VERSION ""

NS_ :

BS_:

BU_: CTRL UUT

BO_ 2565855488 CTRL1: 8 CTRL
 SG_ Command M : 0|6@1+ (1,0) [0|63] ""  UUT
 SG_ Reserved_Prefix : 6|2@1+ (1,0) [0|3] ""  UUT
 SG_ Spare_D5 m1 : 8|2@1+ (1,0) [0|3] ""  UUT
 SG_ Enable_DIGIN m1 : 10|2@1+ (1,0) [0|3] ""  UUT
 SG_ Enable_AD2 m1 : 12|2@1+ (1,0) [0|3] ""  UUT
 SG_ Enable_AD3 m1 : 14|2@1+ (1,0) [0|3] ""  UUT
 SG_ Enable_AD4 m1 : 16|2@1+ (1,0) [0|3] ""  UUT
 SG_ SaveSettings m1 : 18|2@1+ (1,0) [0|3] ""  UUT
 SG_ ADRaw m1 : 20|2@1+ (1,0) [0|3] ""  UUT
 SG_ Reset_Sensor_Power_Faults m1 : 22|2@1+ (1,0) [0|3] ""  UUT
 SG_ Enable_DPLF2 m1 : 24|2@1+ (1,0) [0|3] ""  UUT
 SG_ Enable_FAULT m1 : 26|2@1+ (1,0) [0|3] ""  UUT
 SG_ Ratiometric_AD2_AD3 m1 : 28|2@1+ (1,0) [0|3] ""  UUT
 SG_ Spare_D16 m1 : 30|2@1+ (1,0) [0|3] ""  UUT
 SG_ Protocol_Mode m1 : 32|8@1+ (1,0) [0|255] ""  UUT
 SG_ ID1 m1 : 56|8@1+ (1,0) [0|255] ""  UUT
 SG_ Request_Key m16 : 8|8@1+ (1,0) [0|255] ""  UUT
 SG_ Req_Config_Data_D9 m16 : 16|2@1+ (1,0) [0|3] ""  UUT
 SG_ Req_Calibration_Data_D10 m16 : 18|2@1+ (1,0) [0|3] ""  UUT
 SG_ Reset_Factory_Settings_D11 m16 : 20|2@1+ (1,0) [0|3] ""  UUT
 SG_ Reset_Fault_Counters_D12 m16 : 22|2@1+ (1,0) [0|3] ""  UUT
 SG_ Erase_EEPROM_D13 m16 : 24|2@1+ (1,0) [0|3] ""  UUT
 SG_ Unlock_Key_1 m17 : 8|8@1+ (1,0) [0|255] ""  UUT
 SG_ Unlock_Key_2 m17 : 16|8@1+ (1,0) [0|255] ""  UUT
 SG_ Source_Address_Set m17 : 24|8@1+ (1,0) [0|255] ""  UUT
 SG_ Bit_Rate_Set m17 : 32|8@1+ (1,0) [0|255] ""  UUT
 SG_ CAN_Term_D31 m17 : 60|2@1+ (1,0) [0|3] ""  UUT
 SG_ Reboot_Module_D32 m17 : 62|2@1+ (1,0) [0|3] ""  UUT
 SG_ Information_Index m32 : 8|8@1+ (1,0) [0|255] ""  UUT

BO_ 2565800153 STAT: 8 UUT
 SG_ Response M : 0|6@1+ (1,0) [0|63] ""  CTRL
 SG_ Reserved_Prefix : 6|2@1+ (1,0) [0|3] ""  CTRL
 SG_ Active_Protocol_Mode m0 : 24|8@1+ (1,0) [0|255] ""  CTRL
 SG_ Active_Fault_Code m0 : 32|8@1+ (1,0) [0|255] ""  CTRL
 SG_ UserID m0 : 40|8@1+ (1,0) [0|255] ""  CTRL
 SG_ Software_Version m0 : 48|8@1+ (1,0) [0|255] ""  CTRL
 SG_ Software_Revision m0 : 56|8@1+ (1,0) [0|255] ""  CTRL
 SG_ Spare_D5 m1 : 8|2@1+ (1,0) [0|3] ""  CTRL
 SG_ Enable_DIGIN m1 : 10|2@1+ (1,0) [0|3] ""  CTRL
 SG_ Enable_AD2 m1 : 12|2@1+ (1,0) [0|3] ""  CTRL
 SG_ Enable_AD3 m1 : 14|2@1+ (1,0) [0|3] ""  CTRL
 SG_ Enable_AD4 m1 : 16|2@1+ (1,0) [0|3] ""  CTRL
 SG_ SaveSettings m1 : 18|2@1+ (1,0) [0|3] ""  CTRL
 SG_ ADRaw m1 : 20|2@1+ (1,0) [0|3] ""  CTRL
 SG_ Reset_Sensor_Power_Faults m1 : 22|2@1+ (1,0) [0|3] ""  CTRL
 SG_ Enable_DPLF2 m1 : 24|2@1+ (1,0) [0|3] ""  CTRL
 SG_ Enable_FAULT m1 : 26|2@1+ (1,0) [0|3] ""  CTRL
 SG_ Ratiometric_AD2_AD3 m1 : 28|2@1+ (1,0) [0|3] ""  CTRL
 SG_ Spare_D16 m1 : 30|2@1+ (1,0) [0|3] ""  CTRL
 SG_ Protocol_Mode m1 : 32|8@1+ (1,0) [0|255] ""  CTRL
 SG_ ID1 m1 : 56|8@1+ (1,0) [0|255] ""  CTRL
 SG_ Request_Key m16 : 8|8@1+ (1,0) [0|255] ""  CTRL
 SG_ Req_Config_Data_D9 m16 : 16|2@1+ (1,0) [0|3] ""  CTRL
 SG_ Req_Calibration_Data_D10 m16 : 18|2@1+ (1,0) [0|3] ""  CTRL
 SG_ Reset_Factory_Settings_D11 m16 : 20|2@1+ (1,0) [0|3] ""  CTRL
 SG_ Reset_Fault_Counters_D12 m16 : 22|2@1+ (1,0) [0|3] ""  CTRL
 SG_ Erase_EEPROM_D13 m16 : 24|2@1+ (1,0) [0|3] ""  CTRL
 SG_ Unlock_Key_1 m17 : 8|8@1+ (1,0) [0|255] ""  CTRL
 SG_ Unlock_Key_2 m17 : 16|8@1+ (1,0) [0|255] ""  CTRL
 SG_ Source_Address_Set m17 : 24|8@1+ (1,0) [0|255] ""  CTRL
 SG_ Bit_Rate_Set m17 : 32|8@1+ (1,0) [0|255] ""  CTRL
 SG_ CAN_Term_D31 m17 : 60|2@1+ (1,0) [0|3] ""  CTRL
 SG_ Reboot_Module_D32 m17 : 62|2@1+ (1,0) [0|3] ""  CTRL
 SG_ Info_Data_Byte2 m32 : 8|8@1+ (1,0) [0|255] ""  CTRL
 SG_ Info_Data_Byte3 m32 : 16|8@1+ (1,0) [0|255] ""  CTRL
 SG_ Info_Data_Byte4 m32 : 24|8@1+ (1,0) [0|255] ""  CTRL
 SG_ Info_Data_Byte5 m32 : 32|8@1+ (1,0) [0|255] ""  CTRL
 SG_ Info_Data_Byte6 m32 : 40|8@1+ (1,0) [0|255] ""  CTRL
 SG_ Info_Data_Byte7 m32 : 48|8@1+ (1,0) [0|255] ""  CTRL

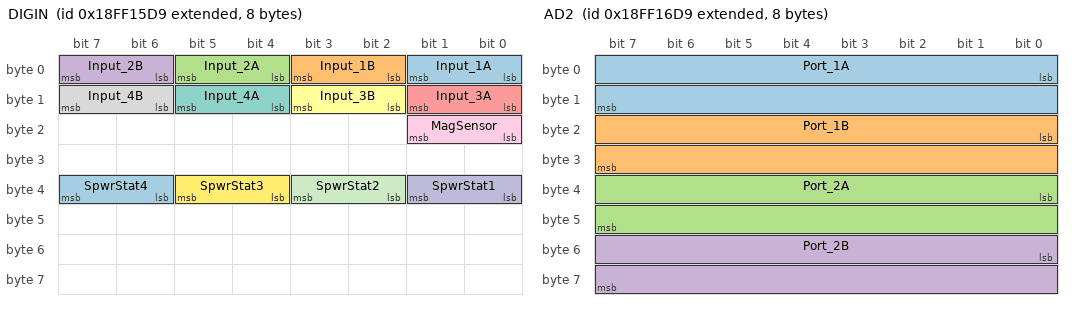
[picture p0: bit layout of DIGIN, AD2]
BO_ 2566854105 DIGIN: 8 UUT
 SG_ Input_1A : 0|2@1+ (1,0) [0|3] ""  CTRL
 SG_ Input_1B : 2|2@1+ (1,0) [0|3] ""  CTRL
 SG_ Input_2A : 4|2@1+ (1,0) [0|3] ""  CTRL
 SG_ Input_2B : 6|2@1+ (1,0) [0|3] ""  CTRL
 SG_ Input_3A : 8|2@1+ (1,0) [0|3] ""  CTRL
 SG_ Input_3B : 10|2@1+ (1,0) [0|3] ""  CTRL
 SG_ Input_4A : 12|2@1+ (1,0) [0|3] ""  CTRL
 SG_ Input_4B : 14|2@1+ (1,0) [0|3] ""  CTRL
 SG_ MagSensor : 16|2@1+ (1,0) [0|3] ""  CTRL
 SG_ SpwrStat1 : 32|2@1+ (1,0) [0|3] ""  CTRL
 SG_ SpwrStat2 : 34|2@1+ (1,0) [0|3] ""  CTRL
 SG_ SpwrStat3 : 36|2@1+ (1,0) [0|3] ""  CTRL
 SG_ SpwrStat4 : 38|2@1+ (1,0) [0|3] ""  CTRL

BO_ 2566854361 AD2: 8 UUT
 SG_ Port_1A : 0|16@1+ (0.001,0) [0|5] "V"  CTRL
 SG_ Port_1B : 16|16@1+ (0.001,0) [0|5] "V"  CTRL
 SG_ Port_2A : 32|16@1+ (0.001,0) [0|5] "V"  CTRL
 SG_ Port_2B : 48|16@1+ (0.001,0) [0|5] "V"  CTRL

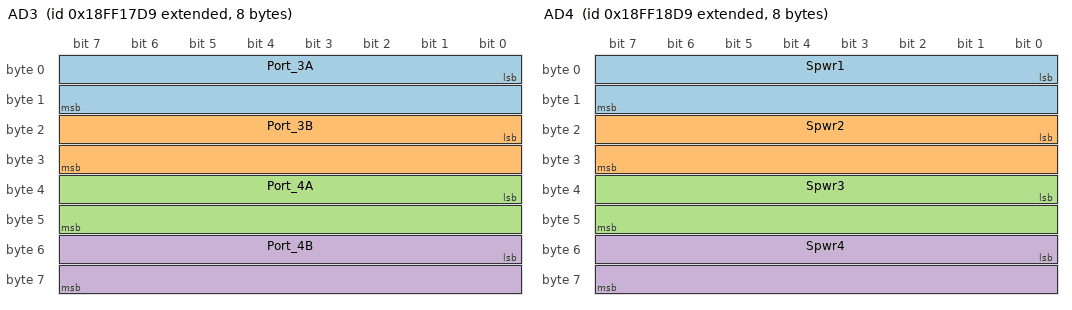
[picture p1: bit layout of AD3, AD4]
BO_ 2566854617 AD3: 8 UUT
 SG_ Port_3A : 0|16@1+ (0.001,0) [0|5] "V"  CTRL
 SG_ Port_3B : 16|16@1+ (0.001,0) [0|5] "V"  CTRL
 SG_ Port_4A : 32|16@1+ (0.001,0) [0|5] "V"  CTRL
 SG_ Port_4B : 48|16@1+ (0.001,0) [0|5] "V"  CTRL

BO_ 2566854873 AD4: 8 UUT
 SG_ Spwr1 : 0|16@1+ (0.001,0) [0|5] "V"  CTRL
 SG_ Spwr2 : 16|16@1+ (0.001,0) [0|5] "V"  CTRL
 SG_ Spwr3 : 32|16@1+ (0.001,0) [0|5] "V"  CTRL
 SG_ Spwr4 : 48|16@1+ (0.001,0) [0|5] "V"  CTRL

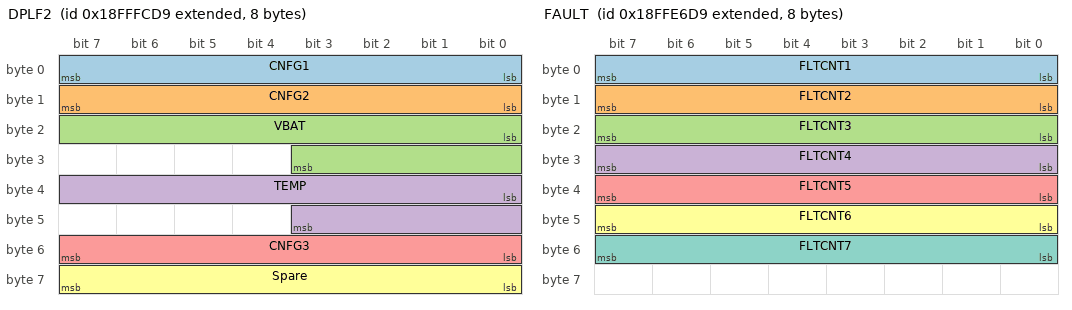
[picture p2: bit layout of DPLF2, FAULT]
BO_ 2566913241 DPLF2: 8 UUT
 SG_ CNFG1 : 0|8@1+ (1,0) [1|50] ""  CTRL
 SG_ CNFG2 : 8|8@1+ (1,0) [1|36] ""  CTRL
 SG_ VBAT : 16|12@1+ (0.1,0) [0|32] "V"  CTRL
 SG_ TEMP : 32|12@1+ (0.1,-100) [-100|300] "degF"  CTRL
 SG_ CNFG3 : 48|8@1+ (1,0) [0|240] ""  CTRL
 SG_ Spare : 56|8@1+ (1,0) [0|255] ""  CTRL

BO_ 2566907609 FAULT: 8 UUT
 SG_ FLTCNT1 : 0|8@1+ (1,0) [0|255] ""  CTRL
 SG_ FLTCNT2 : 8|8@1+ (1,0) [0|255] ""  CTRL
 SG_ FLTCNT3 : 16|8@1+ (1,0) [0|255] ""  CTRL
 SG_ FLTCNT4 : 24|8@1+ (1,0) [0|255] ""  CTRL
 SG_ FLTCNT5 : 32|8@1+ (1,0) [0|255] ""  CTRL
 SG_ FLTCNT6 : 40|8@1+ (1,0) [0|255] ""  CTRL
 SG_ FLTCNT7 : 48|8@1+ (1,0) [0|255] ""  CTRL

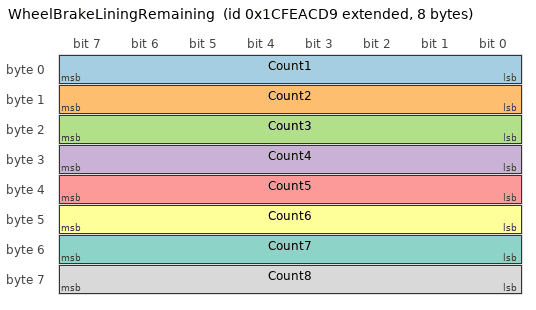
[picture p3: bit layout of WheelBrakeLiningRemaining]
BO_ 2633936089 WheelBrakeLiningRemaining: 8 UUT
 SG_ Count1 : 0|8@1+ (0.4,0) [0|100] "%"  CTRL
 SG_ Count2 : 8|8@1+ (0.4,0) [0|100] "%"  CTRL
 SG_ Count3 : 16|8@1+ (0.4,0) [0|100] "%"  CTRL
 SG_ Count4 : 24|8@1+ (0.4,0) [0|100] "%"  CTRL
 SG_ Count5 : 32|8@1+ (0.4,0) [0|100] "%"  CTRL
 SG_ Count6 : 40|8@1+ (0.4,0) [0|100] "%"  CTRL
 SG_ Count7 : 48|8@1+ (0.4,0) [0|100] "%"  CTRL
 SG_ Count8 : 56|8@1+ (0.4,0) [0|100] "%"  CTRL

CM_ "Generated from the uploaded 43009 CAN specification excerpt. Default module source address is fixed to 0xD9 in this file except for the destination specific Proprietary A messages, which use controller SA placeholder 0x00. Several source tables show decimal 224 alongside hex 0xD9; this DBC follows 0xD9 / 217 because the summary tables and hex fields are internally consistent. AD4 is encoded on 0x18FF18D9 because section 8.10 shows PF/PS 0xFF/0x18 even though the section heading says PGN 65305.";
CM_ BO_ 2565855488 "J1939 Proprietary A control request. The DBC ID uses controller source address placeholder 0x00. Actual runtime CAN ID pattern is 0x18EFD9xx where xx is the controller SA. Byte1 is modeled as a 6-bit command code plus a 2-bit prefix. The provided excerpt is inconsistent about the special raw bytes 0xFE and 0xFF, so those cases are documented through the prefix plus command-code combination rather than a separate full-byte signal.";
CM_ SG_ 2565855488 Command "Logical command code from Byte1 bits 0..5. Known values in the excerpt are 0x00, 0x01, 0x10, 0x11, and 0x20. The summary table also lists special raw bytes 0xFE and 0xFF; these cannot be represented by the 6-bit code alone, so inspect Reserved_Prefix as well.";
CM_ SG_ 2565855488 Reserved_Prefix "Byte1 bits 6..7. Normal command diagrams show a fixed prefix value of binary 10, which decodes here as raw value 2. Special summary-table bytes 0xFE and 0xFF would decode with prefix 3.";
CM_ SG_ 2565855488 Bit_Rate_Set "The excerpt says this byte is CAN bit rate divided by 1000 and that valid values are 250k or 500k. Because the field is only 8 bits wide, 500 cannot be represented literally, so this signal is left as the raw code from the table.";
CM_ BO_ 2565800153 "J1939 Proprietary A response. The DBC ID uses controller source address placeholder 0x00. Actual runtime CAN ID pattern is 0x18EFxxD9 where xx is the controller SA. Response 0x20 payload interpretation depends on the previously requested Information Index, so Byte2..Byte7 are exposed as generic data bytes.";
CM_ SG_ 2565800153 Response "Logical response code from Byte1 bits 0..5. Response payload mirrors the corresponding command layout according to the excerpt.";
CM_ SG_ 2565800153 Reserved_Prefix "Byte1 bits 6..7. Normal response diagrams show a fixed prefix value of binary 10, which decodes here as raw value 2.";
CM_ SG_ 2565800153 Active_Protocol_Mode "Active Protocol Mode";
CM_ SG_ 2565800153 Active_Fault_Code "Active fault code. Value table is populated from section 9 fault codes.";
CM_ SG_ 2565800153 UserID "User ID [ID1]";
CM_ SG_ 2565800153 Software_Version "Firmware Version";
CM_ SG_ 2565800153 Software_Revision "Firmware Revision";
CM_ SG_ 2565800153 Info_Data_Byte2 "For response 0x20, Byte2..Byte7 contain either packed part-number nibbles or MAC address bytes depending on the Information Index that was requested.";
CM_ BO_ 2566854105 "Digital input status. All status items are 2-bit fields. The provided excerpt names the fields but does not define the semantic mapping of raw values 0..3, so they are left as raw 2-bit values.";
CM_ SG_ 2566854105 Input_1A "I/O Status 1A";
CM_ SG_ 2566854105 Input_1B "I/O Status 1B";
CM_ SG_ 2566854105 Input_2A "I/O Status 2A";
CM_ SG_ 2566854105 Input_2B "I/O Status 2B";
CM_ SG_ 2566854105 Input_3A "I/O Status 3A";
CM_ SG_ 2566854105 Input_3B "I/O Status 3B";
CM_ SG_ 2566854105 Input_4A "I/O Status 4A";
CM_ SG_ 2566854105 Input_4B "I/O Status 4B";
CM_ SG_ 2566854105 MagSensor "Mag Sensor";
CM_ SG_ 2566854105 SpwrStat1 "Sensor Power 1 Status";
CM_ SG_ 2566854105 SpwrStat2 "Sensor Power 2 Status";
CM_ SG_ 2566854105 SpwrStat3 "Sensor Power 3 Status";
CM_ SG_ 2566854105 SpwrStat4 "Sensor Power 4 Status";
CM_ BO_ 2566854361 "Analog ports 1A, 1B, 2A, and 2B. Documented range is 0..5000 counts for 0..5 V. This DBC scales to volts using 0.001 V per bit. When ratiometric mode is enabled, the values represent ratio voltage per the specification.";
CM_ SG_ 2566854361 Port_1A "Analog Port1A";
CM_ SG_ 2566854361 Port_1B "Analog Port1B";
CM_ SG_ 2566854361 Port_2A "Analog Port2A";
CM_ SG_ 2566854361 Port_2B "Analog Port2B";
CM_ BO_ 2566854617 "Analog ports 3A, 3B, 4A, and 4B. Documented range is 0..5000 counts for 0..5 V. This DBC scales to volts using 0.001 V per bit. When ratiometric mode is enabled, the values represent ratio voltage per the specification.";
CM_ SG_ 2566854617 Port_3A "Analog Port3A";
CM_ SG_ 2566854617 Port_3B "Analog Port3B";
CM_ SG_ 2566854617 Port_4A "Analog Port4A";
CM_ SG_ 2566854617 Port_4B "Analog Port4B";
CM_ BO_ 2566854873 "Sensor power feedback 1..4. Section 8.10 heading says PGN 65305, but the same table shows PDU Specific 0x18, which corresponds to PGN 0xFF18. This DBC uses 0x18FF18D9 to stay consistent with the PF and PS fields and the AD2/AD3 sequence.";
CM_ SG_ 2566854873 Spwr1 "Sensor Power 1 Feedback";
CM_ SG_ 2566854873 Spwr2 "Sensor Power 2 Feedback";
CM_ SG_ 2566854873 Spwr3 "Sensor Power 3 Feedback";
CM_ SG_ 2566854873 Spwr4 "Sensor Power 4 Feedback";
CM_ BO_ 2566913241 "Status message. VBAT and TEMP are encoded as 12-bit little-endian values using the low nibble of the following byte as the upper 4 bits. CNFG3 is on Byte7 and Spare is on Byte8.";
CM_ SG_ 2566913241 CNFG1 "Hardware Configuration (CNFG1)";
CM_ SG_ 2566913241 CNFG2 "PC Board Revision (CNFG2)";
CM_ SG_ 2566913241 VBAT "Battery voltage. Raw value uses 100 mV per bit with documented range 0..320, decoded here as 0.0..32.0 V.";
CM_ SG_ 2566913241 TEMP "Module temperature. Raw value uses 0.1 degF per bit with a -100 degF offset.";
CM_ SG_ 2566913241 CNFG3 "Additional Configuration (CNFG3)";
CM_ SG_ 2566913241 Spare "Spare";
CM_ BO_ 2566907609 "Fault counter message. The excerpt defines counters F1..F7 but does not map each counter slot to a specific fault code, so the counters are left as raw bytes.";
CM_ SG_ 2566907609 FLTCNT1 "Fault Counter 1";
CM_ SG_ 2566907609 FLTCNT2 "Fault Counter 2";
CM_ SG_ 2566907609 FLTCNT3 "Fault Counter 3";
CM_ SG_ 2566907609 FLTCNT4 "Fault Counter 4";
CM_ SG_ 2566907609 FLTCNT5 "Fault Counter 5";
CM_ SG_ 2566907609 FLTCNT6 "Fault Counter 6";
CM_ SG_ 2566907609 FLTCNT7 "Fault Counter 7";
CM_ BO_ 2633936089 "Wheel brake lining remaining. The DBC scales raw counts 0..250 to 0..100 percent using 0.4 percent per count. Raw value 255 is invalid or faulted. Values 251..254 are not defined by the excerpt.";
CM_ SG_ 2633936089 Count1 "D0 - Count 1";
CM_ SG_ 2633936089 Count2 "D1 - Count 2";
CM_ SG_ 2633936089 Count3 "D2 - Count 3";
CM_ SG_ 2633936089 Count4 "D3 - Count 4";
CM_ SG_ 2633936089 Count5 "D4 - Count 5";
CM_ SG_ 2633936089 Count6 "D5 - Count 6";
CM_ SG_ 2633936089 Count7 "D6 - Count 7";
CM_ SG_ 2633936089 Count8 "D7 - Count 8";
BA_DEF_ BO_  "GenMsgCycleTime" INT 0 2147483647;
BA_DEF_DEF_  "GenMsgCycleTime" 0;
BA_ "GenMsgCycleTime" BO_ 2565855488 50;
BA_ "GenMsgCycleTime" BO_ 2565800153 200;
BA_ "GenMsgCycleTime" BO_ 2566854105 50;
BA_ "GenMsgCycleTime" BO_ 2566854361 50;
BA_ "GenMsgCycleTime" BO_ 2566854617 50;
BA_ "GenMsgCycleTime" BO_ 2566854873 50;
BA_ "GenMsgCycleTime" BO_ 2566913241 200;
BA_ "GenMsgCycleTime" BO_ 2566907609 200;
BA_ "GenMsgCycleTime" BO_ 2633936089 300000;
VAL_ 2565855488 Command 0 "Default_Response" 1 "Module_Configuration" 16 "Factory_Flags" 17 "CAN_Configuration" 32 "Request_Information" 62 "Error_or_NACK_special_raw_byte" 63 "Reserved_or_NO_OP" ;
VAL_ 2565855488 Information_Index 0 "Reserved" 1 "Part_Number" 2 "MAC_Address" 255 "Reserved" ;
VAL_ 2565800153 Response 0 "Default_Response" 1 "Module_Configuration" 16 "Factory_Flags" 17 "CAN_Configuration" 32 "Request_Information" 62 "Error_or_NACK_special_raw_byte" 63 "Reserved_or_NO_OP" ;
VAL_ 2565800153 Active_Fault_Code 7 "EEPROM_Fault" 8 "Voltage_Reference_Fault" 9 "I2C_Communication_Fault" 10 "CNFG_Resistor_Fault" 11 "Magnetic_Sensor_Fault" 12 "Checksum_Fault" 13 "Port_ID_Fault" 14 "CAN_Communication_Fault" 20 "Low_Voltage" 21 "High_Voltage" 31 "Source_Address_Arbitration_Fault" 32 "CAN_Hardware_Fault" 33 "Protocol_Unsuccessful" 34 "Temperature_Fault" 35 "Output_Gate_Driver_Warning" 41 "Low_Voltage_Hold_Enabled" 51 "Output_Overcurrent" 52 "Output_Short_Circuit" 53 "Input_Overvoltage" 54 "Invalid_Input_Configuration" ;
VAL_ 2633936089 Count1 255 "Invalid_or_Faulted" ;
VAL_ 2633936089 Count2 255 "Invalid_or_Faulted" ;
VAL_ 2633936089 Count3 255 "Invalid_or_Faulted" ;
VAL_ 2633936089 Count4 255 "Invalid_or_Faulted" ;
VAL_ 2633936089 Count5 255 "Invalid_or_Faulted" ;
VAL_ 2633936089 Count6 255 "Invalid_or_Faulted" ;
VAL_ 2633936089 Count7 255 "Invalid_or_Faulted" ;
VAL_ 2633936089 Count8 255 "Invalid_or_Faulted" ;
